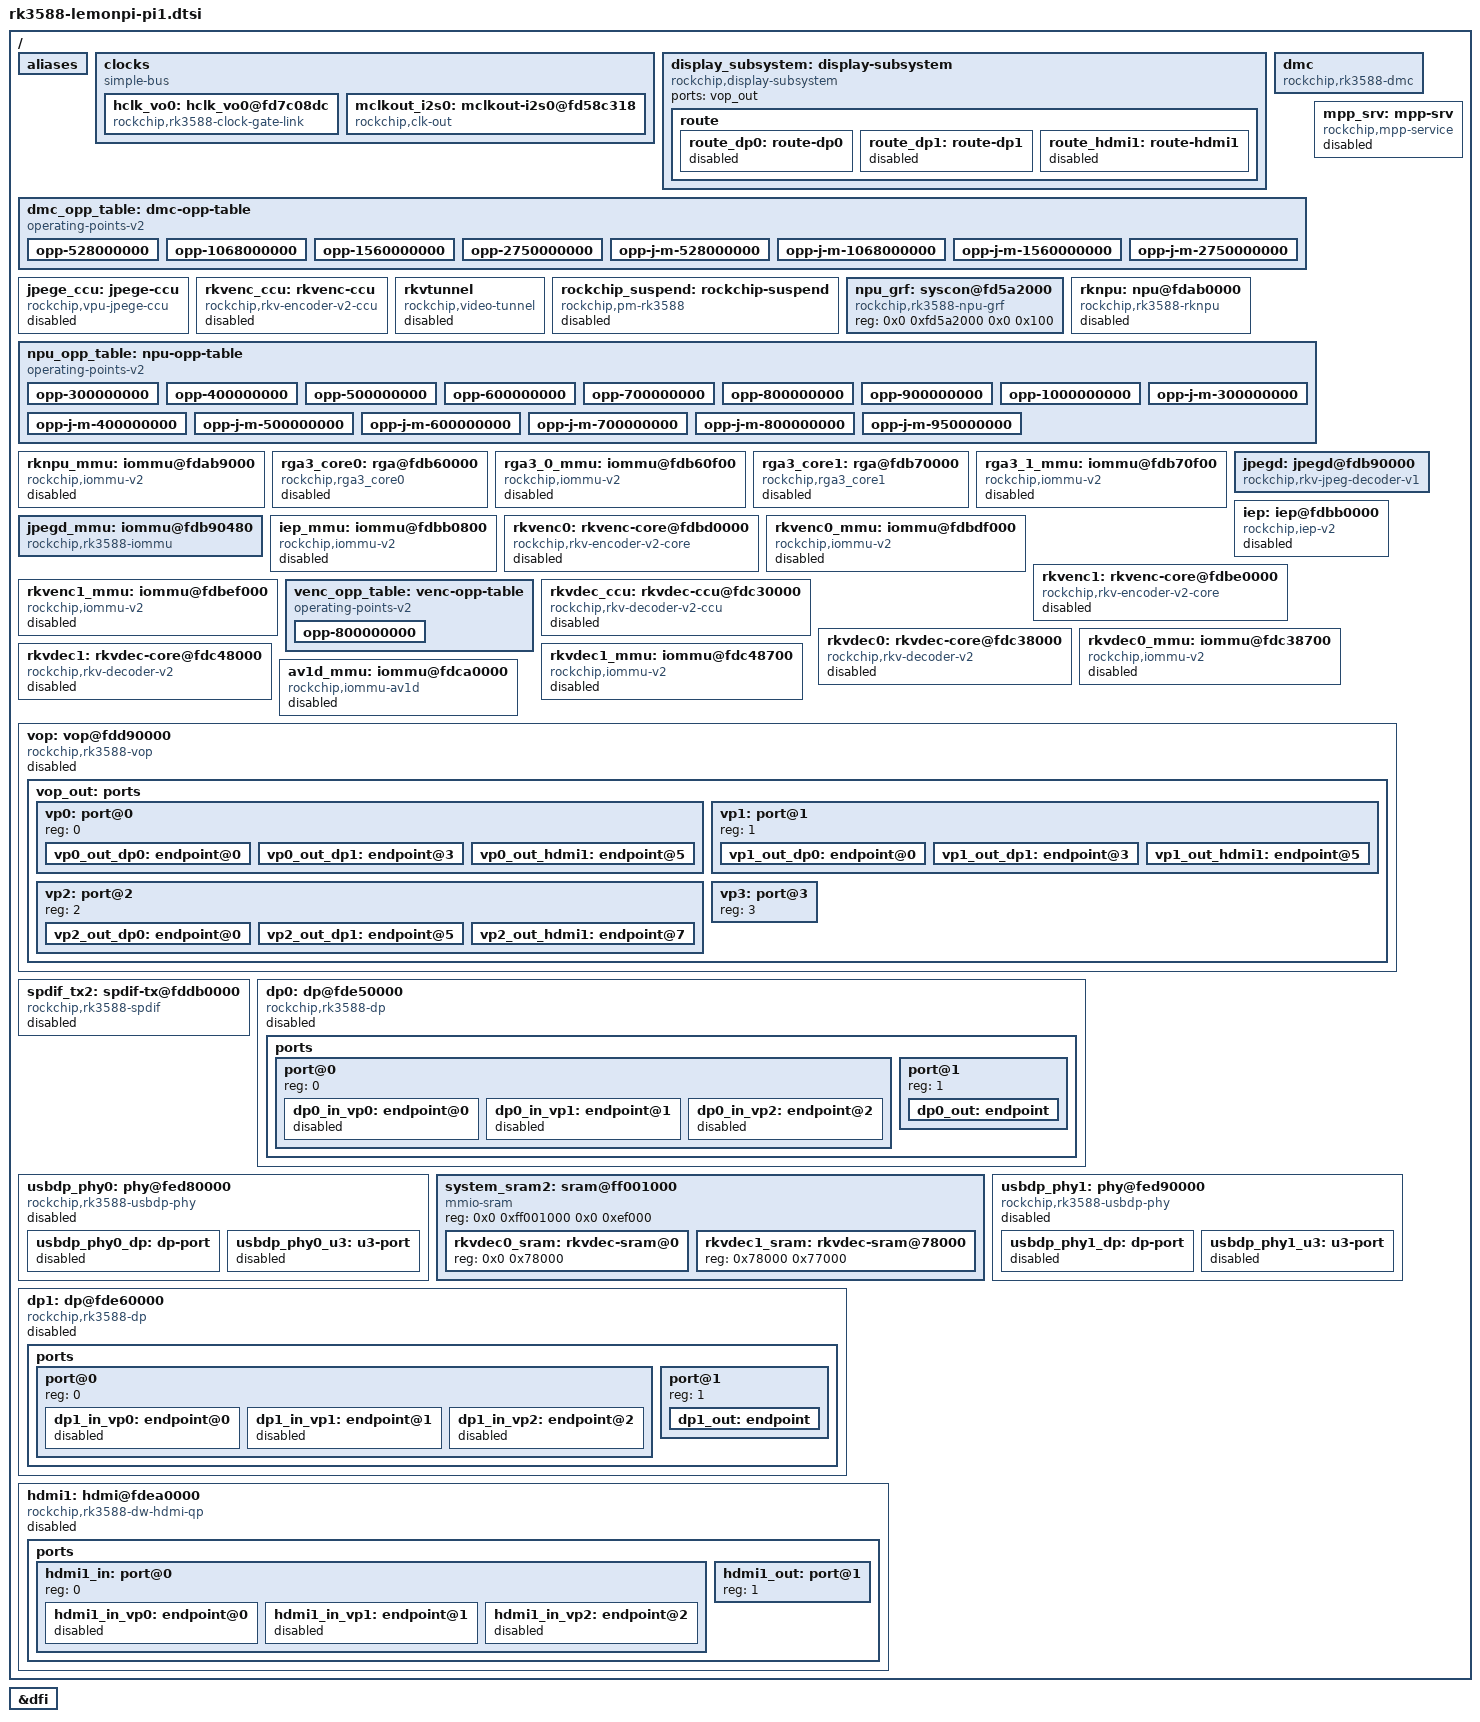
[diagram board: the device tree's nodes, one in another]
// SPDX-License-Identifier: (GPL-2.0+ OR MIT)
/*
 * Copyright (c) 2021 Rockchip Electronics Co., Ltd.
 * 
 * Device Tree Source for LemonPi Pi1 board based on Rockchip RK3588 SoC.
 * Kernel Version Target: 6.1
 *
 */

#include <dt-bindings/soc/rockchip-system-status.h>
#include <dt-bindings/suspend/rockchip-rk3588.h>
#include "rk3588.dtsi"

/ {
	aliases {
		mmc0 = &sdhci;
		mmc1 = &sdmmc;
	};
	 
	clocks {
		compatible = "simple-bus";
		#address-cells = <2>;
		#size-cells = <2>;
		ranges;

		hclk_vo0: hclk_vo0@fd7c08dc {
			compatible = "rockchip,rk3588-clock-gate-link";
			reg = <0 0xfd7c08dc 0 0x10>;
			clock-names = "link";
			clocks = <&cru HCLK_VOP_ROOT>;
			#power-domain-cells = <1>;
			#clock-cells = <0>;
		};

		mclkout_i2s0: mclkout-i2s0@fd58c318 {
			compatible = "rockchip,clk-out";
			reg = <0 0xfd58c318 0 0x4>;
			clocks = <&cru I2S0_8CH_MCLKOUT>;
			#clock-cells = <0>;
			clock-output-names = "i2s0_mclkout_to_io";
			power-domains = <&power RK3588_PD_AUDIO>;
			rockchip,bit-shift = <0>;
			rockchip,bit-set-to-disable;
		};
	};
	
	/* --- rk3588-base --- */
	display_subsystem: display-subsystem {
		compatible = "rockchip,display-subsystem";
		ports = <&vop_out>;

		route {
			
			route_dp0: route-dp0 {
				status = "disabled";
				logo,uboot = "logo.bmp";
				logo,kernel = "logo_kernel.bmp";
				logo,mode = "center";
				charge_logo,mode = "center";
				connect = <&vp1_out_dp0>;
			};

			route_dp1: route-dp1 {
				status = "disabled";
				logo,uboot = "logo.bmp";
				logo,kernel = "logo_kernel.bmp";
				logo,mode = "center";
				charge_logo,mode = "center";
				connect = <&vp1_out_dp1>;
			};

			route_hdmi1: route-hdmi1 {
				status = "disabled";
				logo,uboot = "logo.bmp";
				logo,kernel = "logo_kernel.bmp";
				logo,mode = "center";
				charge_logo,mode = "center";
				connect = <&vp1_out_hdmi1>;
			};
		};
	};

	dmc: dmc {
		compatible = "rockchip,rk3588-dmc";
		interrupts = <GIC_SPI 73 IRQ_TYPE_LEVEL_HIGH 0>;
		interrupt-names = "complete";
		devfreq-events = <&dfi>;
		clocks = <&scmi_clk 4>;
		clock-names = "dmc_clk";
		operating-points-v2 = <&dmc_opp_table>;
		upthreshold = <25>;
		downdifferential = <20>;
		system-status-level = <
			/*system status         freq level*/
			SYS_STATUS_NORMAL       DMC_FREQ_LEVEL_MID_HIGH
			SYS_STATUS_REBOOT       DMC_FREQ_LEVEL_HIGH
			SYS_STATUS_SUSPEND      DMC_FREQ_LEVEL_LOW
			SYS_STATUS_VIDEO_4K     DMC_FREQ_LEVEL_MID_HIGH
			SYS_STATUS_VIDEO_4K_10B DMC_FREQ_LEVEL_MID_HIGH
			SYS_STATUS_VIDEO_SVEP   DMC_FREQ_LEVEL_MID_HIGH
			SYS_STATUS_BOOST        DMC_FREQ_LEVEL_HIGH
			SYS_STATUS_ISP          DMC_FREQ_LEVEL_HIGH
			SYS_STATUS_PERFORMANCE  DMC_FREQ_LEVEL_HIGH
			SYS_STATUS_DUALVIEW     DMC_FREQ_LEVEL_HIGH
			SYS_STATUS_HDMIRX       DMC_FREQ_LEVEL_HIGH
			SYS_STATUS_DEEP_SUSPEND DMC_FREQ_LEVEL_HIGH
		>;
		auto-freq-en = <1>;
		status = "disabled";
	};

	dmc_opp_table: dmc-opp-table {
		compatible = "operating-points-v2";

		nvmem-cells = <&log_leakage>;
		nvmem-cell-names = "leakage", "opp-info", "specification_serial_number";
		rockchip,supported-hw;

		rockchip,leakage-voltage-sel = <
			1	31	0
			32	44	1
			45	57	2
			58	254	3
		>;
		rockchip,temp-hysteresis = <5000>;
		rockchip,low-temp = <15000>;
		rockchip,low-temp-min-volt = <750000>;

		/* RK3588 dmc OPPs */
		opp-528000000 {
			opp-supported-hw = <0xf9 0xffff>;
			opp-hz = /bits/ 64 <528000000>;
			opp-microvolt = <675000 675000 875000>,
					<725000 725000 800000>;
			opp-microvolt-L1 = <675000 675000 875000>,
					   <700000 700000 800000>;
			opp-microvolt-L2 = <675000 675000 875000>,
					   <687500 687500 800000>;
			opp-microvolt-L3 = <675000 675000 875000>,
					   <675000 675000 800000>;
		};
		opp-1068000000 {
			opp-supported-hw = <0xf9 0xffff>;
			opp-hz = /bits/ 64 <1068000000>;
			opp-microvolt = <725000 725000 875000>,
					<737500 737500 800000>;
			opp-microvolt-L1 = <700000 700000 875000>,
					   <712500 712500 800000>;
			opp-microvolt-L2 = <675000 675000 875000>,
					   <700000 700000 800000>;
			opp-microvolt-L3 = <675000 675000 875000>,
					   <687500 687500 800000>;
		};
		opp-1560000000 {
			opp-supported-hw = <0xf9 0xffff>;
			opp-hz = /bits/ 64 <1560000000>;
			opp-microvolt = <800000 800000 875000>,
					<750000 750000 800000>;
			opp-microvolt-L1 = <775000 775000 875000>,
					   <725000 725000 800000>;
			opp-microvolt-L2 = <750000 750000 875000>,
					   <712500 712500 800000>;
			opp-microvolt-L3 = <725000 725000 875000>,
					   <700000 700000 800000>;
		};
		opp-2750000000 {
			opp-supported-hw = <0xf9 0xffff>;
			opp-hz = /bits/ 64 <2750000000>;
			opp-microvolt = <875000 875000 875000>,
					<750000 750000 800000>;
			opp-microvolt-L1 = <850000 850000 875000>,
					   <750000 750000 800000>;
			opp-microvolt-L2 = <837500 837500 875000>,
					   <725000 725000 800000>;
			opp-microvolt-L3 = <825000 820000 875000>,
					   <700000 700000 800000>;
		};

		/* RK3588J/M dmc OPPs */
		opp-j-m-528000000 {
			opp-supported-hw = <0x06 0xffff>;
			opp-hz = /bits/ 64 <528000000>;
			opp-microvolt = <750000 750000 875000>,
					<750000 750000 800000>;
		};
		opp-j-m-1068000000 {
			opp-supported-hw = <0x06 0xffff>;
			opp-hz = /bits/ 64 <1068000000>;
			opp-microvolt = <750000 750000 875000>,
					<750000 750000 800000>;
		};
		opp-j-m-1560000000 {
			opp-supported-hw = <0x06 0xffff>;
			opp-hz = /bits/ 64 <1560000000>;
			opp-microvolt = <800000 800000 875000>,
					<750000 750000 800000>;
			opp-microvolt-L1 = <775000 775000 875000>,
					   <750000 750000 800000>;
			opp-microvolt-L2 = <750000 750000 875000>,
					   <750000 750000 800000>;
			opp-microvolt-L3 = <750000 750000 875000>,
					   <750000 750000 800000>;
		};
		opp-j-m-2750000000 {
			opp-supported-hw = <0x06 0xffff>;
			opp-hz = /bits/ 64 <2750000000>;
			opp-microvolt = <875000 875000 875000>,
					<750000 750000 800000>;
			opp-microvolt-L1 = <850000 850000 875000>,
					   <750000 750000 800000>;
			opp-microvolt-L2 = <837500 837500 875000>,
					   <750000 750000 800000>;
			opp-microvolt-L3 = <825000 820000 875000>,
					   <750000 750000 800000>;
		};
	};

	jpege_ccu: jpege-ccu {
		compatible = "rockchip,vpu-jpege-ccu";
		status = "disabled";
	};

	mpp_srv: mpp-srv {
		compatible = "rockchip,mpp-service";
		rockchip,taskqueue-count = <12>;
		rockchip,resetgroup-count = <1>;
		status = "disabled";
	};

	rkvenc_ccu: rkvenc-ccu {
		compatible = "rockchip,rkv-encoder-v2-ccu";
		status = "disabled";
	};

	rkvtunnel: rkvtunnel {
		compatible = "rockchip,video-tunnel";
		status = "disabled";
	};

	rockchip_suspend: rockchip-suspend {
		compatible = "rockchip,pm-rk3588";
		status = "disabled";
		rockchip,sleep-debug-en = <0>;
		rockchip,sleep-mode-config = <
			(0
			| RKPM_SLP_ARMOFF_LOGOFF
			| RKPM_SLP_PMU_PMUALIVE_32K
			| RKPM_SLP_PMU_DIS_OSC
			| RKPM_SLP_32K_EXT
			)
		>;
		rockchip,wakeup-config = <
			(0
			| RKPM_GPIO_WKUP_EN
			)
		>;
		power-domains = <&power RK3588_PD_USB>;
	};

	npu_grf: syscon@fd5a2000 {
		compatible = "rockchip,rk3588-npu-grf", "syscon";
		reg = <0x0 0xfd5a2000 0x0 0x100>;
	};

	rknpu: npu@fdab0000 {
		compatible = "rockchip,rk3588-rknpu";
		reg = <0x0 0xfdab0000 0x0 0x10000>,
		      <0x0 0xfdac0000 0x0 0x10000>,
		      <0x0 0xfdad0000 0x0 0x10000>;
		interrupts = <GIC_SPI 110 IRQ_TYPE_LEVEL_HIGH 0>,
			     <GIC_SPI 111 IRQ_TYPE_LEVEL_HIGH 0>,
			     <GIC_SPI 112 IRQ_TYPE_LEVEL_HIGH 0>;
		interrupt-names = "npu0_irq", "npu1_irq", "npu2_irq";
		clocks = <&scmi_clk SCMI_CLK_NPU>, <&cru ACLK_NPU0>,
			 <&cru ACLK_NPU1>, <&cru ACLK_NPU2>,
			 <&cru HCLK_NPU0>, <&cru HCLK_NPU1>,
			 <&cru HCLK_NPU2>, <&cru PCLK_NPU_ROOT>;
		clock-names = "clk_npu", "aclk0",
			      "aclk1", "aclk2",
			      "hclk0", "hclk1",
			      "hclk2", "pclk";
		assigned-clocks = <&scmi_clk SCMI_CLK_NPU>;
		assigned-clock-rates = <200000000>;
		resets = <&cru SRST_A_RKNN0>, <&cru SRST_A_RKNN1>, <&cru SRST_A_RKNN2>,
			 <&cru SRST_H_RKNN0>, <&cru SRST_H_RKNN1>, <&cru SRST_H_RKNN2>;
		reset-names = "srst_a0", "srst_a1", "srst_a2",
			      "srst_h0", "srst_h1", "srst_h2";
		power-domains = <&power RK3588_PD_NPUTOP>,
				<&power RK3588_PD_NPU1>,
				<&power RK3588_PD_NPU2>;
		power-domain-names = "npu0", "npu1", "npu2";
		operating-points-v2 = <&npu_opp_table>;
		iommus = <&rknpu_mmu>;
		status = "disabled";
	};

	npu_opp_table: npu-opp-table {
		compatible = "operating-points-v2";


		rockchip,supported-hw;

		rockchip,pvtm-hw = <0x06>;
		rockchip,pvtm-voltage-sel-hw = <
			0	799	0
			800	819	1
			820	844	2
			845	869	3
			870	894	4
			895	9999	5
		>;
		rockchip,pvtm-voltage-sel = <
			0	815	0
			816	835	1
			836	860	2
			861	885	3
			886	910	4
			911	9999	5
		>;
		rockchip,pvtm-pvtpll;
		rockchip,pvtm-offset = <0x50>;
		rockchip,pvtm-sample-time = <1100>;
		rockchip,pvtm-freq = <800000>;
		rockchip,pvtm-volt = <750000>;
		rockchip,pvtm-ref-temp = <25>;
		rockchip,pvtm-temp-prop = <(-113) (-113)>;
		rockchip,pvtm-thermal-zone = "npu-thermal";

		rockchip,opp-clocks = <&cru PCLK_NPU_GRF>, <&cru HCLK_NPU_ROOT>;
		rockchip,grf = <&npu_grf>;
		volt-mem-read-margin = <
			855000	1
			765000	2
			675000	3
			495000	4
		>;
		low-volt-mem-read-margin = <4>;
		intermediate-threshold-freq = <500000>;	/* KHz*/
		rockchip,init-freq = <1000000>;		/* KHz */

		rockchip,temp-hysteresis = <5000>;
		rockchip,low-temp = <15000>;
		rockchip,low-temp-min-volt = <750000>;
		rockchip,high-temp = <85000>;
		rockchip,high-temp-max-freq = <800000>;

		/* RK3588 npu OPPs */
		opp-300000000 {
			opp-supported-hw = <0xf9 0xffff>;
			opp-hz = /bits/ 64 <300000000>;
			opp-microvolt = <700000 700000 850000>,
					<700000 700000 850000>;
			opp-microvolt-L1 = <687500 687500 850000>,
					   <687500 687500 850000>;
			opp-microvolt-L2 = <675000 675000 850000>,
					   <675000 675000 850000>;
			opp-microvolt-L3 = <675000 675000 850000>,
					   <675000 675000 850000>;
			opp-microvolt-L4 = <675000 675000 850000>,
					   <675000 675000 850000>;
			opp-microvolt-L5 = <675000 675000 850000>,
					   <675000 675000 850000>;
		};
		opp-400000000 {
			opp-supported-hw = <0xf9 0xffff>;
			opp-hz = /bits/ 64 <400000000>;
			opp-microvolt = <700000 700000 850000>,
					<700000 700000 850000>;
			opp-microvolt-L1 = <687500 687500 850000>,
					   <687500 687500 850000>;
			opp-microvolt-L2 = <675000 675000 850000>,
					   <675000 675000 850000>;
			opp-microvolt-L3 = <675000 675000 850000>,
					   <675000 675000 850000>;
			opp-microvolt-L4 = <675000 675000 850000>,
					   <675000 675000 850000>;
			opp-microvolt-L5 = <675000 675000 850000>,
					   <675000 675000 850000>;
		};
		opp-500000000 {
			opp-supported-hw = <0xf9 0xffff>;
			opp-hz = /bits/ 64 <500000000>;
			opp-microvolt = <700000 700000 850000>,
					<700000 700000 850000>;
			opp-microvolt-L1 = <687500 687500 850000>,
					   <687500 687500 850000>;
			opp-microvolt-L2 = <675000 675000 850000>,
					   <675000 675000 850000>;
			opp-microvolt-L3 = <675000 675000 850000>,
					   <675000 675000 850000>;
			opp-microvolt-L4 = <675000 675000 850000>,
					   <675000 675000 850000>;
			opp-microvolt-L5 = <675000 675000 850000>,
					   <675000 675000 850000>;
		};
		opp-600000000 {
			opp-supported-hw = <0xf9 0xffff>;
			opp-hz = /bits/ 64 <600000000>;
			opp-microvolt = <700000 700000 850000>,
					<700000 700000 850000>;
			opp-microvolt-L1 = <687500 687500 850000>,
					   <687500 687500 850000>;
			opp-microvolt-L2 = <675000 675000 850000>,
					   <675000 675000 850000>;
			opp-microvolt-L3 = <675000 675000 850000>,
					   <675000 675000 850000>;
			opp-microvolt-L4 = <675000 675000 850000>,
					   <675000 675000 850000>;
			opp-microvolt-L5 = <675000 675000 850000>,
					   <675000 675000 850000>;
		};
		opp-700000000 {
			opp-supported-hw = <0xf9 0xffff>;
			opp-hz = /bits/ 64 <700000000>;
			opp-microvolt = <700000 700000 850000>,
					<700000 700000 850000>;
			opp-microvolt-L3 = <687500 687500 850000>,
					   <687500 687500 850000>;
			opp-microvolt-L4 = <675000 675000 850000>,
					   <675000 675000 850000>;
			opp-microvolt-L5 = <675000 675000 850000>,
					   <675000 675000 850000>;
		};
		opp-800000000 {
			opp-supported-hw = <0xf9 0xffff>;
			opp-hz = /bits/ 64 <800000000>;
			opp-microvolt = <750000 750000 850000>,
					<750000 750000 850000>;
			opp-microvolt-L2 = <737500 737500 850000>,
					   <737500 737500 850000>;
			opp-microvolt-L3 = <725000 725000 850000>,
					   <725000 725000 850000>;
			opp-microvolt-L4 = <712500 712500 850000>,
					   <712500 712500 850000>;
			opp-microvolt-L5 = <700000 700000 850000>,
					   <700000 700000 850000>;
		};
		opp-900000000 {
			opp-supported-hw = <0xf9 0xffff>;
			opp-hz = /bits/ 64 <900000000>;
			opp-microvolt = <800000 800000 850000>,
					<800000 800000 850000>;
			opp-microvolt-L1 = <787500 787500 850000>,
					   <787500 787500 850000>;
			opp-microvolt-L2 = <775000 775000 850000>,
					   <775000 775000 850000>;
			opp-microvolt-L3 = <762500 762500 850000>,
					   <762500 762500 850000>;
			opp-microvolt-L4 = <750000 750000 850000>,
					   <750000 750000 850000>;
			opp-microvolt-L5 = <737500 737500 850000>,
					   <737500 737500 850000>;
		};
		opp-1000000000 {
			opp-supported-hw = <0xf9 0xffff>;
			opp-hz = /bits/ 64 <1000000000>;
			opp-microvolt = <850000 850000 850000>,
					<850000 850000 850000>;
			opp-microvolt-L1 = <837500 837500 850000>,
					   <837500 837500 850000>;
			opp-microvolt-L2 = <825000 825000 850000>,
					   <825000 825000 850000>;
			opp-microvolt-L3 = <812500 812500 850000>,
					   <812500 812500 850000>;
			opp-microvolt-L4 = <800000 800000 850000>,
					   <800000 800000 850000>;
			opp-microvolt-L5 = <787500 787500 850000>,
					   <787500 787500 850000>;
		};

		/* RK3588J/M npu OPPs */
		opp-j-m-300000000 {
			opp-supported-hw = <0x06 0xffff>;
			opp-hz = /bits/ 64 <300000000>;
			opp-microvolt = <750000 750000 850000>,
					<750000 750000 850000>;
		};
		opp-j-m-400000000 {
			opp-supported-hw = <0x06 0xffff>;
			opp-hz = /bits/ 64 <400000000>;
			opp-microvolt = <750000 750000 850000>,
					<750000 750000 850000>;
		};
		opp-j-m-500000000 {
			opp-supported-hw = <0x06 0xffff>;
			opp-hz = /bits/ 64 <500000000>;
			opp-microvolt = <750000 750000 850000>,
					<750000 750000 850000>;
		};
		opp-j-m-600000000 {
			opp-supported-hw = <0x06 0xffff>;
			opp-hz = /bits/ 64 <600000000>;
			opp-microvolt = <750000 750000 850000>,
					<750000 750000 850000>;
		};
		opp-j-m-700000000 {
			opp-supported-hw = <0x06 0xffff>;
			opp-hz = /bits/ 64 <700000000>;
			opp-microvolt = <750000 750000 850000>,
					<750000 750000 850000>;
		};
		opp-j-m-800000000 {
			opp-supported-hw = <0x06 0xffff>;
			opp-hz = /bits/ 64 <800000000>;
			opp-microvolt = <750000 750000 850000>,
					<750000 750000 850000>;
		};
		opp-j-m-950000000 {
			opp-supported-hw = <0x06 0xffff>;
			opp-hz = /bits/ 64 <950000000>;
			opp-microvolt = <837500 837500 850000>,
					<837500 837500 850000>;
			opp-microvolt-L1 = <825000 825000 850000>,
					   <825000 825000 850000>;
			opp-microvolt-L2 = <812500 812500 850000>,
					   <812500 812500 850000>;
			opp-microvolt-L3 = <800000 800000 850000>,
					   <800000 800000 850000>;
			opp-microvolt-L4 = <787500 787500 850000>,
					   <787500 787500 850000>;
			opp-microvolt-L5 = <775000 775000 850000>,
					   <775000 775000 850000>;
		};
	};

	rknpu_mmu: iommu@fdab9000 {
		compatible = "rockchip,iommu-v2";
		reg = <0x0 0xfdab9000 0x0 0x100>,
		      <0x0 0xfdaba000 0x0 0x100>,
		      <0x0 0xfdaca000 0x0 0x100>,
		      <0x0 0xfdada000 0x0 0x100>;
		interrupts = <GIC_SPI 110 IRQ_TYPE_LEVEL_HIGH 0>,
			     <GIC_SPI 111 IRQ_TYPE_LEVEL_HIGH 0>,
			     <GIC_SPI 112 IRQ_TYPE_LEVEL_HIGH 0>;
		interrupt-names = "npu0_mmu", "npu1_mmu", "npu2_mmu";
		clocks = <&cru ACLK_NPU0>, <&cru ACLK_NPU1>, <&cru ACLK_NPU2>,
			 <&cru HCLK_NPU0>, <&cru HCLK_NPU1>, <&cru HCLK_NPU2>;
		clock-names = "aclk0", "aclk1", "aclk2",
			      "iface0", "iface1", "iface2";
		#iommu-cells = <0>;
		status = "disabled";
	};

	rga3_core0: rga@fdb60000 {
		compatible = "rockchip,rga3_core0";
		reg = <0x0 0xfdb60000 0x0 0x1000>;
		interrupts = <GIC_SPI 114 IRQ_TYPE_LEVEL_HIGH 0>;
		interrupt-names = "rga3_core0_irq";
		clocks = <&cru ACLK_RGA3_0>, <&cru HCLK_RGA3_0>, <&cru CLK_RGA3_0_CORE>;
		clock-names = "aclk_rga3_0", "hclk_rga3_0", "clk_rga3_0";
		power-domains = <&power RK3588_PD_RGA30>;
		iommus = <&rga3_0_mmu>;
		status = "disabled";
	};

	rga3_0_mmu: iommu@fdb60f00 {
		compatible = "rockchip,iommu-v2";
		reg = <0x0 0xfdb60f00 0x0 0x100>;
		interrupts = <GIC_SPI 114 IRQ_TYPE_LEVEL_HIGH 0>;
		interrupt-names = "rga3_0_mmu";
		clocks = <&cru ACLK_RGA3_0>, <&cru HCLK_RGA3_0>;
		clock-names = "aclk", "iface";
		power-domains = <&power RK3588_PD_RGA30>;
		#iommu-cells = <0>;
		status = "disabled";
	};

	rga3_core1: rga@fdb70000 {
		compatible = "rockchip,rga3_core1";
		reg = <0x0 0xfdb70000 0x0 0x1000>;
		interrupts = <GIC_SPI 115 IRQ_TYPE_LEVEL_HIGH 0>;
		interrupt-names = "rga3_core1_irq";
		clocks = <&cru ACLK_RGA3_1>, <&cru HCLK_RGA3_1>, <&cru CLK_RGA3_1_CORE>;
		clock-names = "aclk_rga3_1", "hclk_rga3_1", "clk_rga3_1";
		power-domains = <&power RK3588_PD_RGA31>;
		iommus = <&rga3_1_mmu>;
		status = "disabled";
	};

	rga3_1_mmu: iommu@fdb70f00 {
		compatible = "rockchip,iommu-v2";
		reg = <0x0 0xfdb70f00 0x0 0x100>;
		interrupts = <GIC_SPI 115 IRQ_TYPE_LEVEL_HIGH 0>;
		interrupt-names = "rga3_1_mmu";
		clocks = <&cru ACLK_RGA3_1>, <&cru HCLK_RGA3_1>;
		clock-names = "aclk", "iface";
		power-domains = <&power RK3588_PD_RGA31>;
		#iommu-cells = <0>;
		status = "disabled";
	};

	jpegd: jpegd@fdb90000 {
		compatible = "rockchip,rkv-jpeg-decoder-v1";
		reg = <0x0 0xfdb90000 0x0 0x400>;
		interrupts = <GIC_SPI 129 IRQ_TYPE_LEVEL_HIGH 0>;
		clocks = <&cru ACLK_JPEG_DECODER>, <&cru HCLK_JPEG_DECODER>;
		clock-names = "aclk", "hclk";
		power-domains = <&power RK3588_PD_VDPU>;
	};


	jpegd_mmu: iommu@fdb90480 {
		compatible = "rockchip,rk3588-iommu", "rockchip,rk3568-iommu";
		reg = <0x0 0xfdb90480 0x0 0x40>;
		interrupts = <GIC_SPI 130 IRQ_TYPE_LEVEL_HIGH 0>;
		clocks = <&cru ACLK_JPEG_DECODER>, <&cru HCLK_JPEG_DECODER>;
		clock-names = "aclk", "iface";
		power-domains = <&power RK3588_PD_VDPU>;
		#iommu-cells = <0>;
	};


	iep: iep@fdbb0000 {
		compatible = "rockchip,iep-v2";
		reg = <0x0 0xfdbb0000 0x0 0x500>;
		interrupts = <GIC_SPI 117 IRQ_TYPE_LEVEL_HIGH 0>;
		interrupt-names = "irq_iep";
		clocks = <&cru ACLK_IEP2P0>, <&cru HCLK_IEP2P0>, <&cru CLK_IEP2P0_CORE>;
		clock-names = "aclk", "hclk", "sclk";
		rockchip,normal-rates = <594000000>, <0>;
		assigned-clocks = <&cru ACLK_IEP2P0>;
		assigned-clock-rates = <594000000>;
		resets = <&cru SRST_A_IEP2P0>, <&cru SRST_H_IEP2P0>, <&cru SRST_IEP2P0_CORE>;
		reset-names = "rst_a", "rst_h", "rst_s";
		rockchip,skip-pmu-idle-request;
		rockchip,disable-auto-freq;
		power-domains = <&power RK3588_PD_VDPU>;
		rockchip,srv = <&mpp_srv>;
		rockchip,taskqueue-node = <6>;
		iommus = <&iep_mmu>;
		status = "disabled";
	};

	iep_mmu: iommu@fdbb0800 {
		compatible = "rockchip,iommu-v2";
		reg = <0x0 0xfdbb0800 0x0 0x100>;
		interrupts = <GIC_SPI 117 IRQ_TYPE_LEVEL_HIGH 0>;
		interrupt-names = "irq_iep_mmu";
		clocks = <&cru ACLK_IEP2P0>, <&cru HCLK_IEP2P0>;
		clock-names = "aclk", "iface";
		#iommu-cells = <0>;
		power-domains = <&power RK3588_PD_VDPU>;
		status = "disabled";
	};

	rkvenc0: rkvenc-core@fdbd0000 {
		compatible = "rockchip,rkv-encoder-v2-core";
		reg = <0x0 0xfdbd0000 0x0 0x6000>;
		interrupts = <GIC_SPI 101 IRQ_TYPE_LEVEL_HIGH 0>;
		interrupt-names = "irq_rkvenc0";
		clocks = <&cru ACLK_RKVENC0>, <&cru HCLK_RKVENC0>, <&cru CLK_RKVENC0_CORE>;
		clock-names = "aclk_vcodec", "hclk_vcodec", "clk_core";
		rockchip,normal-rates = <500000000>, <0>, <800000000>;
		assigned-clocks = <&cru ACLK_RKVENC0>, <&cru CLK_RKVENC0_CORE>;
		assigned-clock-rates = <500000000>, <800000000>;
		resets = <&cru SRST_A_RKVENC0>, <&cru SRST_H_RKVENC0>, <&cru SRST_RKVENC0_CORE>;
		reset-names = "video_a", "video_h", "video_core";
		rockchip,skip-pmu-idle-request;
		iommus = <&rkvenc0_mmu>;
		rockchip,srv = <&mpp_srv>;
		rockchip,ccu = <&rkvenc_ccu>;
		rockchip,taskqueue-node = <7>;
		rockchip,task-capacity = <8>;
		power-domains = <&power RK3588_PD_VENC0>;
		operating-points-v2 = <&venc_opp_table>;
		status = "disabled";
	};

	rkvenc0_mmu: iommu@fdbdf000 {
		compatible = "rockchip,iommu-v2";
		reg = <0x0 0xfdbdf000 0x0 0x40>, <0x0 0xfdbdf040 0x0 0x40>;
		interrupts = <GIC_SPI 99 IRQ_TYPE_LEVEL_HIGH 0>,
			     <GIC_SPI 100 IRQ_TYPE_LEVEL_HIGH 0>;
		interrupt-names = "irq_rkvenc0_mmu0", "irq_rkvenc0_mmu1";
		clocks = <&cru ACLK_RKVENC0>, <&cru HCLK_RKVENC0>;
		clock-names = "aclk", "iface";
		rockchip,disable-mmu-reset;
		rockchip,enable-cmd-retry;
		rockchip,shootdown-entire;
		#iommu-cells = <0>;
		power-domains = <&power RK3588_PD_VENC0>;
		status = "disabled";
	};

	rkvenc1: rkvenc-core@fdbe0000 {
		compatible = "rockchip,rkv-encoder-v2-core";
		reg = <0x0 0xfdbe0000 0x0 0x6000>;
		interrupts = <GIC_SPI 104 IRQ_TYPE_LEVEL_HIGH 0>;
		interrupt-names = "irq_rkvenc1";
		clocks = <&cru ACLK_RKVENC1>, <&cru HCLK_RKVENC1>, <&cru CLK_RKVENC1_CORE>;
		clock-names = "aclk_vcodec", "hclk_vcodec", "clk_core";
		rockchip,normal-rates = <500000000>, <0>, <800000000>;
		assigned-clocks = <&cru ACLK_RKVENC1>, <&cru CLK_RKVENC1_CORE>;
		assigned-clock-rates = <500000000>, <800000000>;
		resets = <&cru SRST_A_RKVENC1>, <&cru SRST_H_RKVENC1>, <&cru SRST_RKVENC1_CORE>;
		reset-names = "video_a", "video_h", "video_core";
		rockchip,skip-pmu-idle-request;
		iommus = <&rkvenc1_mmu>;
		rockchip,srv = <&mpp_srv>;
		rockchip,ccu = <&rkvenc_ccu>;
		rockchip,taskqueue-node = <7>;
		rockchip,task-capacity = <8>;
		power-domains = <&power RK3588_PD_VENC1>;
		operating-points-v2 = <&venc_opp_table>;
		status = "disabled";
	};

	rkvenc1_mmu: iommu@fdbef000 {
		compatible = "rockchip,iommu-v2";
		reg = <0x0 0xfdbef000 0x0 0x40>, <0x0 0xfdbef040 0x0 0x40>;
		interrupts = <GIC_SPI 102 IRQ_TYPE_LEVEL_HIGH 0>,
			     <GIC_SPI 103 IRQ_TYPE_LEVEL_HIGH 0>;
		interrupt-names = "irq_rkvenc1_mmu0", "irq_rkvenc1_mmu1";
		clocks = <&cru ACLK_RKVENC1>, <&cru HCLK_RKVENC1>;
		lock-names = "aclk", "iface";
		rockchip,disable-mmu-reset;
		rockchip,enable-cmd-retry;
		rockchip,shootdown-entire;
		#iommu-cells = <0>;
		power-domains = <&power RK3588_PD_VENC1>;
		status = "disabled";
	};

	venc_opp_table: venc-opp-table {
		compatible = "operating-points-v2";

		//nvmem-cells = <&codec_leakage>, <&venc_opp_info>;
		nvmem-cell-names = "leakage", "opp-info";
		rockchip,leakage-voltage-sel = <
			1	15	0
			16	25	1
			26	254	2
		>;

		rockchip,grf = <&sys_grf>;
		volt-mem-read-margin = <
			855000	1
			765000	2
			675000	3
			495000	4
		>;

		opp-800000000 {
			opp-hz = /bits/ 64 <800000000>;
			opp-microvolt = <750000 750000 850000>,
					<750000 750000 850000>;
			opp-microvolt-L0 = <800000 800000 850000>,
					   <800000 800000 850000>;
			opp-microvolt-L1 = <775000 775000 850000>,
					   <775000 775000 850000>;
			opp-microvolt-L2 = <750000 750000 850000>,
					   <750000 750000 850000>;
		};
	};

	rkvdec_ccu: rkvdec-ccu@fdc30000 {
		compatible = "rockchip,rkv-decoder-v2-ccu";
		reg = <0x0 0xfdc30000 0x0 0x100>;
		reg-names = "ccu";
		clocks = <&cru ACLK_RKVDEC_CCU>;
		clock-names = "aclk_ccu";
		assigned-clocks = <&cru ACLK_RKVDEC_CCU>;
		assigned-clock-rates = <600000000>;
		resets = <&cru SRST_A_RKVDEC_CCU>;
		reset-names = "video_ccu";
		rockchip,skip-pmu-idle-request;
		/* 1: soft ccu 2: hw ccu */
		rockchip,ccu-mode = <1>;
		power-domains = <&power RK3588_PD_RKVDEC0>;
		status = "disabled";
	};

	rkvdec0: rkvdec-core@fdc38000 {
		compatible = "rockchip,rkv-decoder-v2";
		reg = <0x0 0xfdc38100 0x0 0x400>, <0x0 0xfdc38000 0x0 0x100>;
		reg-names = "regs", "link";
		interrupts = <GIC_SPI 95 IRQ_TYPE_LEVEL_HIGH 0>;
		interrupt-names = "irq_rkvdec0";
		clocks = <&cru ACLK_RKVDEC0>, <&cru HCLK_RKVDEC0>, <&cru CLK_RKVDEC0_CORE>,
			 <&cru CLK_RKVDEC0_CA>, <&cru CLK_RKVDEC0_HEVC_CA>;
		clock-names = "aclk_vcodec", "hclk_vcodec", "clk_core",
			      "clk_cabac", "clk_hevc_cabac";
		rockchip,normal-rates = <800000000>, <0>, <600000000>,
					<600000000>, <1000000000>;
		assigned-clocks = <&cru ACLK_RKVDEC0>, <&cru CLK_RKVDEC0_CORE>,
				  <&cru CLK_RKVDEC0_CA>, <&cru CLK_RKVDEC0_HEVC_CA>;
		assigned-clock-rates = <800000000>, <600000000>,
				       <600000000>, <1000000000>;
		resets = <&cru SRST_A_RKVDEC0>, <&cru SRST_H_RKVDEC0>, <&cru SRST_RKVDEC0_CORE>,
			 <&cru SRST_RKVDEC0_CA>, <&cru SRST_RKVDEC0_HEVC_CA>;
		reset-names = "video_a", "video_h", "video_core",
			      "video_cabac", "video_hevc_cabac";
		rockchip,skip-pmu-idle-request;
		iommus = <&rkvdec0_mmu>;
		rockchip,srv = <&mpp_srv>;
		rockchip,ccu = <&rkvdec_ccu>;
		rockchip,core-mask = <0x00010001>;
		rockchip,task-capacity = <16>;
		rockchip,taskqueue-node = <9>;
		rockchip,sram = <&rkvdec0_sram>;
		/* rcb_iova: start and size 1M@4095M */
		rockchip,rcb-iova = <0xFFF00000 0x100000>;
		rockchip,rcb-info = <136 24576>, <137 49152>, <141 90112>, <140 49152>,
				    <139 180224>, <133 49152>, <134 8192>, <135 4352>,
				    <138 13056>, <142 291584>;
		rockchip,rcb-min-width = <512>;
		power-domains = <&power RK3588_PD_RKVDEC0>;
		status = "disabled";
	};

	rkvdec0_mmu: iommu@fdc38700 {
		compatible = "rockchip,iommu-v2";
		reg = <0x0 0xfdc38700 0x0 0x40>, <0x0 0xfdc38740 0x0 0x40>;
		interrupts = <GIC_SPI 96 IRQ_TYPE_LEVEL_HIGH 0>;
		interrupt-names = "irq_rkvdec0_mmu";
		clocks = <&cru ACLK_RKVDEC0>, <&cru HCLK_RKVDEC0>;
		clock-names = "aclk", "iface";
		rockchip,disable-mmu-reset;
		rockchip,enable-cmd-retry;
		rockchip,shootdown-entire;
		rockchip,master-handle-irq;
		#iommu-cells = <0>;
		power-domains = <&power RK3588_PD_RKVDEC0>;
		status = "disabled";
	};

	rkvdec1: rkvdec-core@fdc48000 {
		compatible = "rockchip,rkv-decoder-v2";
		reg = <0x0 0xfdc48100 0x0 0x400>, <0x0 0xfdc48000 0x0 0x100>;
		reg-names = "regs", "link";
		interrupts = <GIC_SPI 97 IRQ_TYPE_LEVEL_HIGH 0>;
		interrupt-names = "irq_rkvdec1";
		clocks = <&cru ACLK_RKVDEC1>, <&cru HCLK_RKVDEC1>, <&cru CLK_RKVDEC1_CORE>,
			 <&cru CLK_RKVDEC1_CA>, <&cru CLK_RKVDEC1_HEVC_CA>;
		clock-names = "aclk_vcodec", "hclk_vcodec", "clk_core",
			      "clk_cabac", "clk_hevc_cabac";
		rockchip,normal-rates = <800000000>, <0>, <600000000>,
					<600000000>, <1000000000>;
		assigned-clocks = <&cru ACLK_RKVDEC1>, <&cru CLK_RKVDEC1_CORE>,
				  <&cru CLK_RKVDEC1_CA>, <&cru CLK_RKVDEC1_HEVC_CA>;
		assigned-clock-rates = <800000000>, <600000000>,
				       <600000000>, <1000000000>;
		resets = <&cru SRST_A_RKVDEC1>, <&cru SRST_H_RKVDEC1>, <&cru SRST_RKVDEC1_CORE>,
			 <&cru SRST_RKVDEC1_CA>, <&cru SRST_RKVDEC1_HEVC_CA>;
		reset-names = "video_a", "video_h", "video_core",
			      "video_cabac", "video_hevc_cabac";
		rockchip,skip-pmu-idle-request;
		iommus = <&rkvdec1_mmu>;
		rockchip,srv = <&mpp_srv>;
		rockchip,ccu = <&rkvdec_ccu>;
		rockchip,core-mask = <0x00020002>;
		rockchip,task-capacity = <16>;
		rockchip,taskqueue-node = <9>;
		rockchip,sram = <&rkvdec1_sram>;
		/* rcb_iova: start and size 1M@4094M */
		rockchip,rcb-iova = <0xFFE00000 0x100000>;
		rockchip,rcb-info = <136 24576>, <137 49152>, <141 90112>, <140 49152>,
				    <139 180224>, <133 49152>, <134 8192>, <135 4352>,
				    <138 13056>, <142 291584>;
		rockchip,rcb-min-width = <512>;
		power-domains = <&power RK3588_PD_RKVDEC1>;
		status = "disabled";
	};

	rkvdec1_mmu: iommu@fdc48700 {
		compatible = "rockchip,iommu-v2";
		reg = <0x0 0xfdc48700 0x0 0x40>, <0x0 0xfdc48740 0x0 0x40>;
		interrupts = <GIC_SPI 98 IRQ_TYPE_LEVEL_HIGH 0>;
		interrupt-names = "irq_rkvdec1_mmu";
		clocks = <&cru ACLK_RKVDEC1>, <&cru HCLK_RKVDEC1>;
		clock-names = "aclk", "iface";
		rockchip,disable-mmu-reset;
		rockchip,enable-cmd-retry;
		rockchip,shootdown-entire;
		rockchip,master-handle-irq;
		#iommu-cells = <0>;
		power-domains = <&power RK3588_PD_RKVDEC1>;
		status = "disabled";
	};

		av1d_mmu: iommu@fdca0000 {
		compatible = "rockchip,iommu-av1d";
		reg = <0x0 0xfdca0000 0x0 0x600>;
		interrupts = <GIC_SPI 109 IRQ_TYPE_LEVEL_HIGH>;
		interrupt-names = "irq_av1d_mmu";
		clocks = <&cru ACLK_AV1>, <&cru PCLK_AV1>;
		clock-names = "aclk", "iface";
		#iommu-cells = <0>;
		power-domains = <&power RK3588_PD_AV1>;
		status = "disabled";
	};
	/* --- rk3588-base --- */
	vop: vop@fdd90000 {
		compatible = "rockchip,rk3588-vop";
		reg = <0x0 0xfdd90000 0x0 0x4200>, <0x0 0xfdd95000 0x0 0x1000>;
		reg-names = "vop", "gamma-lut";
		interrupts = <GIC_SPI 156 IRQ_TYPE_LEVEL_HIGH 0>;
		clocks = <&cru ACLK_VOP>,
			 <&cru HCLK_VOP>,
			 <&cru DCLK_VOP0>,
			 <&cru DCLK_VOP1>,
			 <&cru DCLK_VOP2>,
			 <&cru DCLK_VOP3>,
			 <&cru PCLK_VOP_ROOT>,
			 <&hdptxphy0>;
		clock-names = "aclk",
			      "hclk",
			      "dclk_vp0",
			      "dclk_vp1",
			      "dclk_vp2",
			      "dclk_vp3",
			      "pclk_vop",
			      "pll_hdmiphy0";
		iommus = <&vop_mmu>;
		power-domains = <&power RK3588_PD_VOP>;
		rockchip,grf = <&sys_grf>;
		rockchip,vop-grf = <&vop_grf>;
		rockchip,vo1-grf = <&vo1_grf>;
		rockchip,pmu = <&pmu>;
		status = "disabled";

		vop_out: ports {
			#address-cells = <1>;
			#size-cells = <0>;

			vp0: port@0 {
				#address-cells = <1>;
				#size-cells = <0>;
				reg = <0>;
				vp0_out_dp0: endpoint@0 {
					reg = <0>;
					remote-endpoint = <&dp0_in_vp0>;
				};
			};

			vp1: port@1 {
				#address-cells = <1>;
				#size-cells = <0>;
				reg = <1>;
				
				vp1_out_dp0: endpoint@0 {
					reg = <0>;
					remote-endpoint = <&dp0_in_vp1>;
				};
			};

			vp2: port@2 {
				#address-cells = <1>;
				#size-cells = <0>;
				reg = <2>;
				vp2_out_dp0: endpoint@0 {
					reg = <0>;
					remote-endpoint = <&dp0_in_vp2>;
				};
			};

			vp3: port@3 {
				#address-cells = <1>;
				#size-cells = <0>;
				reg = <3>;
			};
		};
	};

	spdif_tx2: spdif-tx@fddb0000 {
		compatible = "rockchip,rk3588-spdif", "rockchip,rk3568-spdif";
		reg = <0x0 0xfddb0000 0x0 0x1000>;
		interrupts = <GIC_SPI 195 IRQ_TYPE_LEVEL_HIGH 0>;
		dmas = <&dmac1 6>;
		dma-names = "tx";
		clock-names = "mclk", "hclk";
		clocks = <&cru MCLK_SPDIF2>, <&cru HCLK_SPDIF2_DP0>;
		assigned-clocks = <&cru CLK_SPDIF2_DP0_SRC>;
		assigned-clock-parents = <&cru PLL_AUPLL>;
		power-domains = <&power RK3588_PD_VO0>;
		#sound-dai-cells = <0>;
		status = "disabled";
	};

	dp0: dp@fde50000 {
		compatible = "rockchip,rk3588-dp";
		reg = <0x0 0xfde50000 0x0 0x4000>;
		interrupts = <GIC_SPI 161 IRQ_TYPE_LEVEL_HIGH 0>;
		clocks = <&cru PCLK_DP0>, <&cru CLK_AUX16M_0>,
			 <&cru MCLK_I2S4_8CH_TX>, <&cru MCLK_SPDIF2_DP0>,
			 <&hclk_vo0>, <&cru CLK_DP0>;
		clock-names = "apb", "aux", "i2s", "spdif", "hclk", "hdcp";
		assigned-clocks = <&cru CLK_AUX16M_0>;
		assigned-clock-rates = <16000000>;
		resets = <&cru SRST_DP0>;
		phys = <&usbdp_phy0_dp>;
		power-domains = <&power RK3588_PD_VO0>;
		#sound-dai-cells = <1>;
		status = "disabled";

		ports {
			#address-cells = <1>;
			#size-cells = <0>;

			port@0 {
				reg = <0>;
				#address-cells = <1>;
				#size-cells = <0>;

				dp0_in_vp0: endpoint@0 {
					reg = <0>;
					remote-endpoint = <&vp0_out_dp0>;
					status = "disabled";
				};

				dp0_in_vp1: endpoint@1 {
					reg = <1>;
					remote-endpoint = <&vp1_out_dp0>;
					status = "disabled";
				};

				dp0_in_vp2: endpoint@2 {
					reg = <2>;
					remote-endpoint = <&vp2_out_dp0>;
					status = "disabled";
				};
			};

			port@1 {
				reg = <1>;

				dp0_out: endpoint { };
			};
		};
	};

	/* --- rk3588-base --- */
	usbdp_phy0: phy@fed80000 {
		compatible = "rockchip,rk3588-usbdp-phy";
		reg = <0x0 0xfed80000 0x0 0x10000>;
		#phy-cells = <1>;
		clocks = <&cru CLK_USBDPPHY_MIPIDCPPHY_REF>,
			 <&cru CLK_USBDP_PHY0_IMMORTAL>,
			 <&cru PCLK_USBDPPHY0>,
			 <&u2phy0>;
		clock-names = "refclk", "immortal", "pclk", "utmi";
		resets = <&cru SRST_USBDP_COMBO_PHY0_INIT>,
			 <&cru SRST_USBDP_COMBO_PHY0_CMN>,
			 <&cru SRST_USBDP_COMBO_PHY0_LANE>,
			 <&cru SRST_USBDP_COMBO_PHY0_PCS>,
			 <&cru SRST_P_USBDPPHY0>;
		reset-names = "init", "cmn", "lane", "pcs_apb", "pma_apb";
		rockchip,u2phy-grf = <&usb2phy0_grf>;
		rockchip,usb-grf = <&usb_grf>;
		rockchip,usbdpphy-grf = <&usbdpphy0_grf>;
		rockchip,vo-grf = <&vo0_grf>;
		status = "disabled";
		
		usbdp_phy0_dp: dp-port {
			#phy-cells = <0>;
			status = "disabled";
		};

		usbdp_phy0_u3: u3-port {
			#phy-cells = <0>;
			status = "disabled";
		};
	};
	/* --- rk3588-base --- */
	system_sram2: sram@ff001000 {
		compatible = "mmio-sram";
		reg = <0x0 0xff001000 0x0 0xef000>;
		ranges = <0x0 0x0 0xff001000 0xef000>;
		#address-cells = <1>;
		#size-cells = <1>;
		rkvdec0_sram: rkvdec-sram@0 {
			reg = <0x0 0x78000>;
		};
		rkvdec1_sram: rkvdec-sram@78000 {
			reg = <0x78000 0x77000>;
		};
	};

	dp1: dp@fde60000 {
		compatible = "rockchip,rk3588-dp";
		reg = <0x0 0xfde60000 0x0 0x4000>;
		interrupts = <GIC_SPI 162 IRQ_TYPE_LEVEL_HIGH 0>;
		clocks = <&cru PCLK_DP1>, <&cru CLK_AUX16M_1>,
			 <&cru MCLK_I2S8_8CH_TX>, <&cru MCLK_SPDIF5_DP1>,
			 <&hclk_vo0>, <&cru CLK_DP1>;
		clock-names = "apb", "aux", "i2s", "spdif", "hclk", "hdcp";
		assigned-clocks = <&cru CLK_AUX16M_1>;
		assigned-clock-rates = <16000000>;
		resets = <&cru SRST_DP1>;
		phys = <&usbdp_phy1_dp>;
		power-domains = <&power RK3588_PD_VO0>;
		#sound-dai-cells = <1>;
		status = "disabled";

		ports {
			#address-cells = <1>;
			#size-cells = <0>;

			port@0 {
				reg = <0>;
				#address-cells = <1>;
				#size-cells = <0>;

				dp1_in_vp0: endpoint@0 {
					reg = <0>;
					remote-endpoint = <&vp0_out_dp1>;
					status = "disabled";
				};

				dp1_in_vp1: endpoint@1 {
					reg = <1>;
					remote-endpoint = <&vp1_out_dp1>;
					status = "disabled";
				};

				dp1_in_vp2: endpoint@2 {
					reg = <2>;
					remote-endpoint = <&vp2_out_dp1>;
					status = "disabled";
				};
			};

			port@1 {
				reg = <1>;

				dp1_out: endpoint { };
			};
		};
	};

	/* --- rk3588-extra --- */
	hdmi1: hdmi@fdea0000 {
		compatible = "rockchip,rk3588-dw-hdmi-qp";
		reg = <0x0 0xfdea0000 0x0 0x20000>;
		clocks = <&cru PCLK_HDMITX1>,
			 <&cru CLK_HDMITX1_EARC>,
			 <&cru CLK_HDMITX1_REF>,
			 <&cru MCLK_I2S6_8CH_TX>,
			 <&cru CLK_HDMIHDP1>,
			 <&cru HCLK_VO1>;
		clock-names = "pclk", "earc", "ref", "aud", "hdp", "hclk_vo1";
		interrupts = <GIC_SPI 173 IRQ_TYPE_LEVEL_HIGH 0>,
			     <GIC_SPI 174 IRQ_TYPE_LEVEL_HIGH 0>,
			     <GIC_SPI 175 IRQ_TYPE_LEVEL_HIGH 0>,
			     <GIC_SPI 176 IRQ_TYPE_LEVEL_HIGH 0>,
			     <GIC_SPI 361 IRQ_TYPE_LEVEL_HIGH 0>;
		interrupt-names = "avp", "cec", "earc", "main", "hpd";
		phys = <&hdptxphy1>;
		pinctrl-names = "default";
		pinctrl-0 = <&hdmim2_tx1_cec &hdmim0_tx1_hpd
			     &hdmim1_tx1_scl &hdmim1_tx1_sda>;
		power-domains = <&power RK3588_PD_VO1>;
		resets = <&cru SRST_HDMITX1_REF>, <&cru SRST_HDMIHDP1>;
		reset-names = "ref", "hdp";
		rockchip,grf = <&sys_grf>;
		rockchip,vo-grf = <&vo1_grf>;
		#sound-dai-cells = <0>;
		status = "disabled";

		ports {
			#address-cells = <1>;
			#size-cells = <0>;

			hdmi1_in: port@0 {
				reg = <0>;
				#address-cells = <1>;
				#size-cells = <0>;

				hdmi1_in_vp0: endpoint@0 {
					reg = <0>;
					remote-endpoint = <&vp0_out_hdmi1>;
					status = "disabled";
				};

				hdmi1_in_vp1: endpoint@1 {
					reg = <1>;
					remote-endpoint = <&vp1_out_hdmi1>;
					status = "disabled";
				};

				hdmi1_in_vp2: endpoint@2 {
					reg = <2>;
					remote-endpoint = <&vp2_out_hdmi1>;
					status = "disabled";
				};
			};

			hdmi1_out: port@1 {
				reg = <1>;
			};
		};
	};
	 /* --- rk3588-extra --- */
	usbdp_phy1: phy@fed90000 {
		compatible = "rockchip,rk3588-usbdp-phy";
		reg = <0x0 0xfed90000 0x0 0x10000>;
		#phy-cells = <1>;
		clocks = <&cru CLK_USBDPPHY_MIPIDCPPHY_REF>,
			 <&cru CLK_USBDP_PHY1_IMMORTAL>,
			 <&cru PCLK_USBDPPHY1>,
			 <&u2phy1>;
		clock-names = "refclk", "immortal", "pclk", "utmi";
		resets = <&cru SRST_USBDP_COMBO_PHY1_INIT>,
			 <&cru SRST_USBDP_COMBO_PHY1_CMN>,
			 <&cru SRST_USBDP_COMBO_PHY1_LANE>,
			 <&cru SRST_USBDP_COMBO_PHY1_PCS>,
			 <&cru SRST_P_USBDPPHY1>;
		reset-names = "init", "cmn", "lane", "pcs_apb", "pma_apb";
		rockchip,u2phy-grf = <&usb2phy1_grf>;
		rockchip,usb-grf = <&usb_grf>;
		rockchip,usbdpphy-grf = <&usbdpphy1_grf>;
		rockchip,vo-grf = <&vo0_grf>;
		status = "disabled";
		usbdp_phy1_dp: dp-port {
			#phy-cells = <0>;
			status = "disabled";
		};

		usbdp_phy1_u3: u3-port {
			#phy-cells = <0>;
			status = "disabled";
		};
	};
};

&dfi {
	status = "okay";
};

&dmc {
	status = "okay";
	center-supply = <&vdd_ddr_s0>;
	mem-supply = <&vdd_log_s0>;
};

&vp0 {
	vp0_out_dp1: endpoint@3 {
		reg = <3>;
		remote-endpoint = <&dp1_in_vp0>;
	};
	vp0_out_hdmi1: endpoint@5 {
		reg = <5>;
		remote-endpoint = <&hdmi1_in_vp0>;
	};
};

&vp1 {
	vp1_out_dp1: endpoint@3 {
		reg = <3>;
		remote-endpoint = <&dp1_in_vp1>;
	};
	vp1_out_hdmi1: endpoint@5 {
		reg = <5>;
		remote-endpoint = <&hdmi1_in_vp1>;
	};
};

&vp2 {
	vp2_out_dp1: endpoint@5 {
		reg = <5>;
		remote-endpoint = <&dp1_in_vp2>;
	};
	vp2_out_hdmi1: endpoint@7 {
		reg = <7>;
		remote-endpoint = <&hdmi1_in_vp2>;
	};
};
